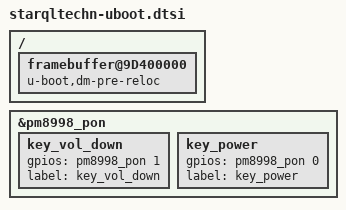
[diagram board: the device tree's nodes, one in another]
// SPDX-License-Identifier: GPL-2.0+
/*
 * U-Boot addition to handle Samsung S9 SM-G9600 (starqltechn) pins
 *
 * (C) Copyright 2021 Dzmitry Sankouski <dsankouski@gmail.com>
 *
 */

/
{
	framebuffer@9D400000 {
		u-boot,dm-pre-reloc;
	};
};

&pm8998_pon {
	key_vol_down {
		gpios = <&pm8998_pon 1 0>;
		label = "key_vol_down";
	};
	key_power {
		gpios = <&pm8998_pon 0 0>;
		label = "key_power";
	};
};
